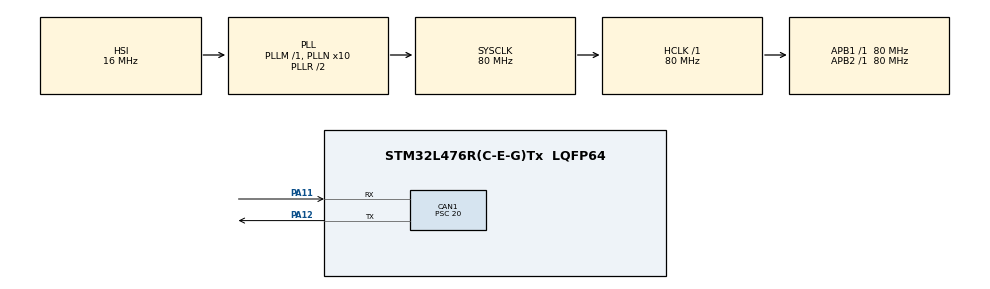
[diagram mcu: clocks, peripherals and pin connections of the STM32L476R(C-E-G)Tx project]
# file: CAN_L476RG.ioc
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CAN1.BS1=CAN_BS1_3TQ
CAN1.BS2=CAN_BS2_4TQ
CAN1.CalculateBaudRate=500000
CAN1.CalculateTimeBit=2000.00
CAN1.CalculateTimeQuantum=250.0
CAN1.Prescaler=20
Mcu.Family=STM32L4
Mcu.Name=STM32L476R(C-E-G)Tx
Mcu.Package=LQFP64
NVIC.CAN1_RX0_IRQn=true\:0\:0\:false\:false\:true\:true\:true
NVIC.PriorityGroup=NVIC_PRIORITYGROUP_4
NVIC.TIM1_TRG_COM_TIM17_IRQn=true\:15\:0\:false\:false\:true\:false\:true
NVIC.TimeBase=TIM1_TRG_COM_TIM17_IRQn
NVIC.TimeBaseIP=TIM17
PA11.Mode=CAN_Activate
PA11.Signal=CAN1_RX
PA12.Mode=CAN_Activate
PA12.Signal=CAN1_TX
ProjectManager.HeapSize=0x200
ProjectManager.StackSize=0x400
ProjectManager.TargetToolchain=STM32CubeIDE
RCC.ADCFreq_Value=64000000
RCC.AHBFreq_Value=80000000
RCC.APB1Freq_Value=80000000
RCC.APB1TimFreq_Value=80000000
RCC.APB2Freq_Value=80000000
RCC.APB2TimFreq_Value=80000000
RCC.CortexFreq_Value=80000000
RCC.HCLKFreq_Value=80000000
RCC.HSE_VALUE=8000000
RCC.HSI_VALUE=16000000
RCC.MSI_VALUE=4000000
RCC.PLLN=10
RCC.PLLSourceVirtual=RCC_PLLSOURCE_HSI
RCC.PREFETCH_ENABLE=1
RCC.SYSCLKFreq_VALUE=80000000
RCC.SYSCLKSource=RCC_SYSCLKSOURCE_PLLCLK
RCC.USBFreq_Value=64000000
RCC.VCOOutputFreq_Value=160000000
VP_SYS_VS_tim17.Mode=TIM17
board=NUCLEO-L476RG

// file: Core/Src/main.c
/* USER CODE BEGIN Header */
/**
  ******************************************************************************
  * @file           : main.c
  * @brief          : Main program body
  ******************************************************************************
  * @attention
  *
  * <h2><center>&copy; Copyright (c) 2021 STMicroelectronics.
  * All rights reserved.</center></h2>
  *
  * This software component is licensed by ST under BSD 3-Clause license,
  * the "License"; You may not use this file except in compliance with the
  * License. You may obtain a copy of the License at:
  *                        opensource.org/licenses/BSD-3-Clause
  *
  ******************************************************************************
  */
/* USER CODE END Header */
#include "main.h"

CAN_HandleTypeDef hcan1;

void SystemClock_Config(void);
static void MX_GPIO_Init(void);
static void MX_CAN1_Init(void);

/* USER CODE BEGIN 0 */

CAN_TxHeaderTypeDef TxHeader;
CAN_RxHeaderTypeDef RxHeader;

int TX = 1;
int RX = 0;

uint8_t TxData[8];
uint8_t RxData[8];

uint32_t TxMailbox;

int datacheck = 0;
int status = 0;

/* USER CODE END 0 */

int main(void)
{
  /* USER CODE BEGIN 1 */

	TxData[0] = 5;
	TxData[1] = 1;
	TxData[2] = 0xFF;
	TxData[3] = 0x0;
	TxData[4] = 0xFF;
	TxData[5] = 0x0;
	TxData[6] = 0xFF;
	TxData[7] = 0x0;

  /* USER CODE END 1 */

  /* MCU Configuration--------------------------------------------------------*/

  /* Reset of all peripherals, Initializes the Flash interface and the Systick. */
  HAL_Init();

  /* Configure the system clock */
  SystemClock_Config();

  /* Initialize all configured peripherals */
  MX_GPIO_Init();
  MX_CAN1_Init();
  /* USER CODE BEGIN 2 */
  HAL_CAN_Start(&hcan1);
  HAL_CAN_ActivateNotification(&hcan1, CAN_IT_RX_FIFO0_MSG_PENDING);
  TxHeader.DLC = 8; //Data length
  TxHeader.IDE = CAN_ID_STD;
  TxHeader.RTR = CAN_RTR_DATA;
  TxHeader.StdId = 0x100; //Sender ID

  /* USER CODE END 2 */

  /* Infinite loop */
  /* USER CODE BEGIN WHILE */
  while (1)
  {

	   // HAL_CAN_AddTxMessage(&hcan1, &TxHeader, TxData, &TxMailbox);
	  	if(HAL_CAN_AddTxMessage(&hcan1, &TxHeader, TxData, &TxMailbox) == HAL_OK){
	  		status = 2000;
	  	}
	  	else{
	  		status = 3000;
	  		}

	  	HAL_Delay(1000);
    /* USER CODE END WHILE */

  }
}

void SystemClock_Config(void)
{
  RCC_OscInitTypeDef RCC_OscInitStruct = {0};
  RCC_ClkInitTypeDef RCC_ClkInitStruct = {0};

  /** Configure the main internal regulator output voltage
  */
  if (HAL_PWREx_ControlVoltageScaling(PWR_REGULATOR_VOLTAGE_SCALE1) != HAL_OK)
  {
    Error_Handler();
  }
  /** Initializes the RCC Oscillators according to the specified parameters
  * in the RCC_OscInitTypeDef structure.
  */
  RCC_OscInitStruct.OscillatorType = RCC_OSCILLATORTYPE_HSI;
  RCC_OscInitStruct.HSIState = RCC_HSI_ON;
  RCC_OscInitStruct.HSICalibrationValue = RCC_HSICALIBRATION_DEFAULT;
  RCC_OscInitStruct.PLL.PLLState = RCC_PLL_ON;
  RCC_OscInitStruct.PLL.PLLSource = RCC_PLLSOURCE_HSI;
  RCC_OscInitStruct.PLL.PLLM = 1;
  RCC_OscInitStruct.PLL.PLLN = 10;
  RCC_OscInitStruct.PLL.PLLP = RCC_PLLP_DIV7;
  RCC_OscInitStruct.PLL.PLLQ = RCC_PLLQ_DIV2;
  RCC_OscInitStruct.PLL.PLLR = RCC_PLLR_DIV2;
  if (HAL_RCC_OscConfig(&RCC_OscInitStruct) != HAL_OK)
  {
    Error_Handler();
  }
  /** Initializes the CPU, AHB and APB buses clocks
  */
  RCC_ClkInitStruct.ClockType = RCC_CLOCKTYPE_HCLK|RCC_CLOCKTYPE_SYSCLK
                              |RCC_CLOCKTYPE_PCLK1|RCC_CLOCKTYPE_PCLK2;
  RCC_ClkInitStruct.SYSCLKSource = RCC_SYSCLKSOURCE_PLLCLK;
  RCC_ClkInitStruct.AHBCLKDivider = RCC_SYSCLK_DIV1;
  RCC_ClkInitStruct.APB1CLKDivider = RCC_HCLK_DIV1;
  RCC_ClkInitStruct.APB2CLKDivider = RCC_HCLK_DIV1;

  if (HAL_RCC_ClockConfig(&RCC_ClkInitStruct, FLASH_LATENCY_4) != HAL_OK)
  {
    Error_Handler();
  }
}

static void MX_CAN1_Init(void)
{

  hcan1.Instance = CAN1;
  hcan1.Init.Prescaler = 20;
  hcan1.Init.Mode = CAN_MODE_NORMAL;
  hcan1.Init.SyncJumpWidth = CAN_SJW_1TQ;
  hcan1.Init.TimeSeg1 = CAN_BS1_3TQ;
  hcan1.Init.TimeSeg2 = CAN_BS2_4TQ;
  hcan1.Init.TimeTriggeredMode = DISABLE;
  hcan1.Init.AutoBusOff = DISABLE;
  hcan1.Init.AutoWakeUp = DISABLE;
  hcan1.Init.AutoRetransmission = DISABLE;
  hcan1.Init.ReceiveFifoLocked = DISABLE;
  hcan1.Init.TransmitFifoPriority = DISABLE;
  if (HAL_CAN_Init(&hcan1) != HAL_OK)
  {
    Error_Handler();
  }
  /* USER CODE BEGIN CAN1_Init 2 */
  CAN_FilterTypeDef canfilterconfig;
   canfilterconfig.FilterActivation = CAN_FILTER_ENABLE;
   canfilterconfig.FilterBank = 0;
   canfilterconfig.FilterFIFOAssignment = CAN_FILTER_FIFO0;
   canfilterconfig.FilterIdHigh = 0x0<<5;
   canfilterconfig.FilterIdLow = 0;
   canfilterconfig.FilterMaskIdHigh = 0x0<<5;
   canfilterconfig.FilterMaskIdLow = 0x0000;
   canfilterconfig.FilterMode = CAN_FILTERMODE_IDMASK;
   canfilterconfig.FilterScale = CAN_FILTERSCALE_32BIT;
   canfilterconfig.SlaveStartFilterBank = 20;

   HAL_CAN_ConfigFilter(&hcan1, &canfilterconfig);

  /* USER CODE END CAN1_Init 2 */

}

static void MX_GPIO_Init(void)
{

  /* GPIO Ports Clock Enable */
  __HAL_RCC_GPIOA_CLK_ENABLE();

}

void HAL_TIM_PeriodElapsedCallback(TIM_HandleTypeDef *htim)
{
  if (htim->Instance == TIM17) {
    HAL_IncTick();
  }
}

void Error_Handler(void)
{
  __disable_irq();
  while (1)
  {
  }
}

/************************ (C) COPYRIGHT STMicroelectronics *****END OF FILE****/
